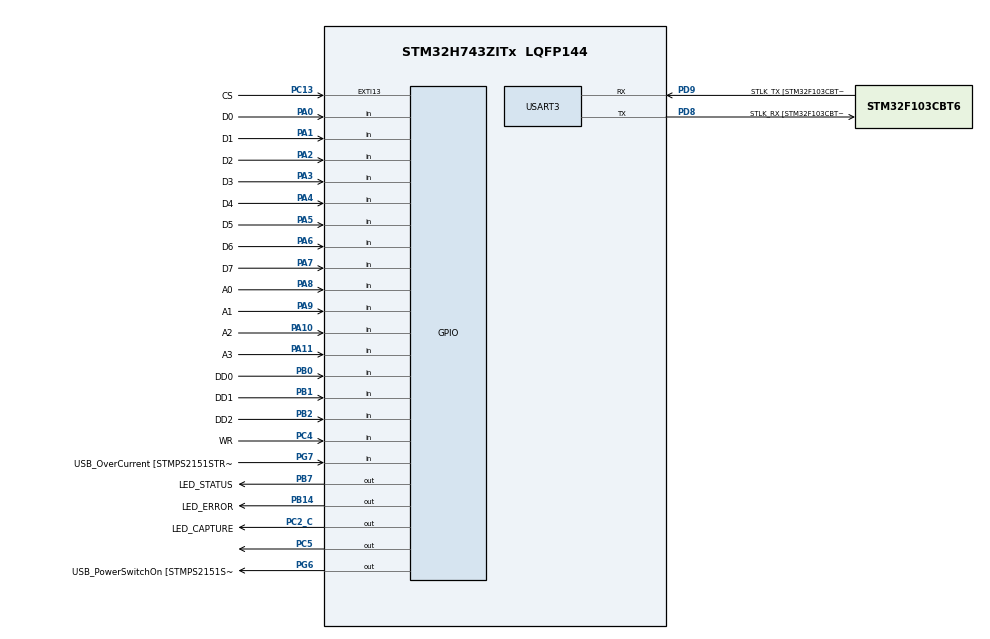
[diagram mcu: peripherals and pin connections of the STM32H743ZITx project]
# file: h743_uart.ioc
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Dma.Request0=USART3_TX
Dma.USART3_TX.0.Direction=DMA_MEMORY_TO_PERIPH
Dma.USART3_TX.0.EventEnable=DISABLE
Dma.USART3_TX.0.FIFOMode=DMA_FIFOMODE_DISABLE
Dma.USART3_TX.0.Instance=DMA1_Stream3
Dma.USART3_TX.0.MemDataAlignment=DMA_MDATAALIGN_BYTE
Dma.USART3_TX.0.MemInc=DMA_MINC_ENABLE
Dma.USART3_TX.0.Mode=DMA_NORMAL
Dma.USART3_TX.0.PeriphDataAlignment=DMA_PDATAALIGN_BYTE
Dma.USART3_TX.0.PeriphInc=DMA_PINC_DISABLE
Dma.USART3_TX.0.Polarity=HAL_DMAMUX_REQ_GEN_RISING
Dma.USART3_TX.0.Priority=DMA_PRIORITY_LOW
Dma.USART3_TX.0.RequestNumber=1
Dma.USART3_TX.0.SignalID=NONE
Dma.USART3_TX.0.SyncEnable=DISABLE
Dma.USART3_TX.0.SyncPolarity=HAL_DMAMUX_SYNC_NO_EVENT
Dma.USART3_TX.0.SyncRequestNumber=1
Dma.USART3_TX.0.SyncSignalID=NONE
Mcu.Family=STM32H7
Mcu.Name=STM32H743ZITx
Mcu.Package=LQFP144
NVIC.DMA1_Stream3_IRQn=true\:0\:0\:false\:false\:true\:false\:true
NVIC.EXTI15_10_IRQn=true\:0\:0\:false\:false\:true\:true\:true
NVIC.PriorityGroup=NVIC_PRIORITYGROUP_4
NVIC.USART3_IRQn=true\:0\:0\:false\:false\:true\:true\:true
PA0.GPIO_Label=D0
PA0.GPIO_PuPd=GPIO_NOPULL
PA0.Signal=GPIO_Input
PA1.GPIO_Label=D1
PA1.GPIO_PuPd=GPIO_NOPULL
PA1.Signal=GPIO_Input
PA10.GPIO_Label=A2
PA10.Signal=GPIO_Input
PA11.GPIO_Label=A3
PA11.Signal=GPIO_Input
PA12.GPIO_Label=USB_DP
PA12.Signal=USB_OTG_FS_DP
PA2.GPIO_Label=D2
PA2.GPIO_PuPd=GPIO_NOPULL
PA2.Signal=GPIO_Input
PA3.GPIO_Label=D3
PA3.Signal=GPIO_Input
PA4.GPIO_Label=D4
PA4.Signal=GPIO_Input
PA5.GPIO_Label=D5
PA5.Signal=GPIO_Input
PA6.GPIO_Label=D6
PA6.Signal=GPIO_Input
PA7.GPIO_Label=D7
PA7.Signal=GPIO_Input
PA8.GPIO_Label=A0
PA8.Signal=GPIO_Input
PA9.GPIO_Label=A1
PA9.Signal=GPIO_Input
PB0.GPIO_Label=DD0
PB0.GPIO_PuPd=GPIO_PULLUP
PB0.Signal=GPIO_Input
PB1.GPIO_Label=DD1
PB1.GPIO_PuPd=GPIO_PULLUP
PB1.Signal=GPIO_Input
PB13.GPIO_Label=RMII_TXD1
PB13.Signal=ETH_TXD1
PB14.GPIO_Label=LED_ERROR
PB14.GPIO_Speed=GPIO_SPEED_FREQ_VERY_HIGH
PB14.Signal=GPIO_Output
PB2.GPIO_Label=DD2
PB2.GPIO_PuPd=GPIO_PULLUP
PB2.Signal=GPIO_Input
PB7.GPIO_FM7=SYSCFG_PMCR_I2C_PB7_FMP
PB7.GPIO_Label=LED_STATUS
PB7.GPIO_Speed=GPIO_SPEED_FREQ_VERY_HIGH
PB7.Signal=GPIO_Output
PC1.GPIO_Label=RMII_MDC
PC1.Signal=ETH_MDC
PC13.GPIO_Label=CS
PC13.GPIO_ModeDefaultEXTI=GPIO_MODE_IT_FALLING
PC13.GPIO_PuPd=GPIO_PULLUP
PC13.Signal=GPXTI13
PC14-OSC32_IN\ (OSC32_IN).Mode=LSE-External-Oscillator
PC14-OSC32_IN\ (OSC32_IN).Signal=RCC_OSC32_IN
PC15-OSC32_OUT\ (OSC32_OUT).Mode=LSE-External-Oscillator
PC15-OSC32_OUT\ (OSC32_OUT).Signal=RCC_OSC32_OUT
PC2_C.GPIO_Label=LED_CAPTURE
PC2_C.GPIO_Speed=GPIO_SPEED_FREQ_VERY_HIGH
PC2_C.Signal=GPIO_Output
PC4.GPIO_Label=WR
PC4.GPIO_PuPd=GPIO_PULLUP
PC4.Signal=GPIO_Input
PC5.Signal=GPIO_Output
PD8.GPIO_Label=STLK_RX [STM32F103CBT6_PA3]
PD8.Mode=Asynchronous
PD8.Signal=USART3_TX
PD9.GPIO_Label=STLK_TX [STM32F103CBT6_PA2]
PD9.Mode=Asynchronous
PD9.Signal=USART3_RX
PG11.GPIO_Label=RMII_TX_EN
PG11.Signal=ETH_TX_EN
PG13.GPIO_Label=RMII_TXD0
PG13.Signal=ETH_TXD0
PG6.GPIO_Label=USB_PowerSwitchOn [STMPS2151STR_EN]
PG6.Signal=GPIO_Output
PG7.GPIO_Label=USB_OverCurrent [STMPS2151STR_FAULT]
PG7.Signal=GPIO_Input
PH0-OSC_IN\ (PH0).GPIO_Label=MCO
PH0-OSC_IN\ (PH0).Mode=HSE-External-Clock-Source
PH0-OSC_IN\ (PH0).Signal=RCC_OSC_IN
PH1-OSC_OUT\ (PH1).Signal=RCC_OSC_OUT
ProjectManager.HeapSize=0x200
ProjectManager.StackSize=0x1000
ProjectManager.TargetToolchain=STM32CubeIDE
RCC.48MHZClocksFreq_Value=24000000
RCC.ADCFreq_Value=16125000
RCC.AHBFreq_Value=216000000
RCC.APB1CLKDivider=RCC_HCLK_DIV4
RCC.APB1Freq_Value=120000000
RCC.APB1TimFreq_Value=108000000
RCC.APB2CLKDivider=RCC_HCLK_DIV2
RCC.APB2Freq_Value=120000000
RCC.APB2TimFreq_Value=216000000
RCC.APB3Freq_Value=120000000
RCC.APB4Freq_Value=120000000
RCC.CortexFreq_Value=480000000
RCC.D1PPRE=RCC_APB3_DIV2
RCC.D2PPRE1=RCC_APB1_DIV2
RCC.D2PPRE2=RCC_APB2_DIV2
RCC.D3PPRE=RCC_APB4_DIV2
RCC.DIVM1=1
RCC.DIVN1=120
RCC.DIVQ1=4
RCC.HCLKFreq_Value=240000000
RCC.HPRE=RCC_HCLK_DIV2
RCC.HSE_VALUE=8000000
RCC.HSI_VALUE=64000000
RCC.PLLFRACN=0
RCC.PLLM=25
RCC.PLLMUL=RCC_PLL_MUL9
RCC.PLLN=432
RCC.PLLQ=9
RCC.PLLSourceVirtual=RCC_PLLSOURCE_HSE
RCC.PRESCALERUSB=RCC_USBCLKSOURCE_PLL_DIV1_5
RCC.PWR_Regulator_Voltage_Scale=PWR_REGULATOR_VOLTAGE_SCALE0
RCC.SYSCLKFreq_VALUE=480000000
RCC.SYSCLKSource=RCC_SYSCLKSOURCE_PLLCLK
RCC.SYSCLKSourceVirtual=RCC_SYSCLKSOURCE_PLLCLK
RCC.USBFreq_Value=240000000
RCC.VCOOutputFreq_Value=432000000
USART3.VirtualMode-Asynchronous=VM_ASYNC
board=NUCLEO-H743ZI

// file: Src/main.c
/* USER CODE BEGIN Header */
/**
  ******************************************************************************
  * @file           : main.c
  * @brief          : Main program body
  ******************************************************************************
  * @attention
  *
  * <h2><center>&copy; Copyright (c) 2020 STMicroelectronics.
  * All rights reserved.</center></h2>
  *
  * This software component is licensed by ST under BSD 3-Clause license,
  * the "License"; You may not use this file except in compliance with the
  * License. You may obtain a copy of the License at:
  *                        opensource.org/licenses/BSD-3-Clause
  *
  ******************************************************************************
  */
/* USER CODE END Header */
#include "main.h"

/* USER CODE BEGIN Includes */
#include "ticker.h"
#include "frame.h"
#include "frame_com.h"
#include "evse_com_app.h"
#include "app_uart_fifo.h"
#include "serial3.h"
#include "io_input.h"
#include "input_service.h"
/* USER CODE END Includes */

UART_HandleTypeDef huart3;
DMA_HandleTypeDef hdma_usart3_tx;
DMA_HandleTypeDef hdma_usart3_rx;

/* USER CODE BEGIN PV */
static app_uart_fifo_ctx_t	uart_instance3;

static rfid_frame_handle_t	rfid_frame_handle;

static io_input_cxt_t            button_cxt     = IO_INPUT_DEFAULT;
static service_io_input_handle_t button_service = SERVICE_IO_INPUT_DEFAULT;
static ticker_function_handle_t  tick_button_sample;

static ticker_function_handle_t  tick_led_status;

static char const * button_serviceid[] = {
/* 0 */ "IO_INPUT_FALLING",
/* 1 */ "IO_INPUT_RISING",
/* 2 */ "BUTTON_SINGER_EVT",
/* 3 */ "BUTTON_DOUBLE_EVT",
/* 4 */ "BUTTON_HOLD_ON_EVT",
/* 5 */ "BUTTON_IDLE_EVT"
};

/* USER CODE END PV */

void SystemClock_Config(void);
static void MX_GPIO_Init(void);
static void MX_DMA_Init(void);
static void MX_USART3_UART_Init(void);

/* USER CODE BEGIN 0 */
/**
  * @brief  Tx Transfer completed callback
  * @param  huart: UART handle.
  * @note   This example shows a simple way to report end of DMA Tx transfer, and
  *         you can add your own implementation.
  * @retval None
  */
void HAL_UART_TxCpltCallback(UART_HandleTypeDef *huart)
{
	if (huart->Instance == USART3)
	{
		uart_instance3.irq_callback(&uart_instance3, APP_UART_IRQ_TX);
	}
}

void HAL_UART_RxCpltCallback(UART_HandleTypeDef *huart)
{
	if (huart->Instance == USART3)
	{
#if (defined APP_UART_FIFO_RX_DMA) && (APP_UART_FIFO_RX_DMA == 1)
		/* Get head position of rx_irq buffer
		 * __HAL_DMA_GET_COUNTER() is the macro return number of remaining data units in the current DMA Stream transfer */
		uart_instance3.rx_irq.head = uart_instance3.rx_irq.xfer_size - __HAL_DMA_GET_COUNTER(&hdma_usart3_rx);
		uart_instance3.irq_callback(&uart_instance3, APP_UART_IRQ_RX);
#else
		/* Get head position of rx_irq buffer
		* huart->RxXferCount shall return number of remaining data units in the current rx_irq buffer */
		uart_instance3.rx_irq.head = uart_instance3.rx_irq.xfer_size - huart->RxXferCount;
		uart_instance3.irq_callback(&uart_instance3, APP_UART_IRQ_RX);
#endif
	}
}

void HAL_UART_RxHalfCpltCallback(UART_HandleTypeDef *huart)
{
	if (huart->Instance == USART3)
	{
#if (defined APP_UART_FIFO_RX_DMA) && (APP_UART_FIFO_RX_DMA == 1)
		/* Get head position of rx_irq buffer
		 * __HAL_DMA_GET_COUNTER() is the macro return number of remaining data units in the current DMA Stream transfer */
		uart_instance3.rx_irq.head = uart_instance3.rx_irq.xfer_size - __HAL_DMA_GET_COUNTER(&hdma_usart3_rx);
		/* Using case APP_UART_IRQ_IDLE instead APP_UART_IRQ_RX because this isn't irq complete yet */
		uart_instance3.irq_callback(&uart_instance3, APP_UART_IRQ_IDLE);
#else
		/* Get head position of rx_irq buffer
		* huart->RxXferCount shall return number of remaining data units in the current rx_irq buffer */
		uart_instance3.rx_irq.head = uart_instance3.rx_irq.xfer_size - huart->RxXferCount;
		/* Using case APP_UART_IRQ_IDLE instead APP_UART_IRQ_RX because this isn't irq complete yet */
		uart_instance3.irq_callback(&uart_instance3, APP_UART_IRQ_IDLE);
#endif
	}
}

void USART_IDLE_line_IRQHandler(UART_HandleTypeDef *huart)
{
	if (huart->Instance == USART3)
	{
		if (__HAL_UART_GET_FLAG(huart, UART_FLAG_IDLE))
		{
			/* Clear IDLE line flag */
			__HAL_UART_CLEAR_FLAG(huart, UART_CLEAR_IDLEF);

#if (defined APP_UART_FIFO_RX_DMA) && (APP_UART_FIFO_RX_DMA == 1)
			/* Get head position of rx_irq buffer
			 * __HAL_DMA_GET_COUNTER() is the macro return number of remaining data units in the current DMA Stream transfer */
			uart_instance3.rx_irq.head = uart_instance3.rx_irq.xfer_size - __HAL_DMA_GET_COUNTER(&hdma_usart3_rx);
			/* Using case APP_UART_IRQ_IDLE instead APP_UART_IRQ_RX because this isn't irq complete yet */
			uart_instance3.irq_callback(&uart_instance3, APP_UART_IRQ_IDLE);
#else
			/* Get head position of rx_irq buffer
			* huart->RxXferCount shall return number of remaining data units in the current rx_irq buffer */
			uart_instance3.rx_irq.head = uart_instance3.rx_irq.xfer_size - huart->RxXferCount;
			/* Using case APP_UART_IRQ_IDLE instead APP_UART_IRQ_RX because this isn't irq complete yet */
			uart_instance3.irq_callback(&uart_instance3, APP_UART_IRQ_IDLE);
#endif
		}
	}
}

/* Event callback app_uart_fifo */
static void uart_instance3_event_handle(struct app_uart_fifo_ctx *p_app_cxt, app_uart_evt_t *p_event)
{
	if (p_app_cxt == &uart_instance3)
	{
		switch (p_event->evt_type)
		{
		case EVT_APP_UART_TX_READY:
			break;

		case EVT_APP_UART_RX_READY:
			break;

		case EVT_APP_UART_TX_EMPTY:
			break;

		case EVT_APP_UART_RX_EMPTY:
			break;

		case EVT_APP_UART_TX_OVER:
			break;

		case EVT_APP_UART_RX_OVER:
			break;

		case EVT_APP_UART_DATA_READY:
			break;

		case EVT_APP_UART_DATA_SENDING:
			break;

		case EVT_APP_UART_TX_FIFO_ERROR:
			break;

		case EVT_APP_UART_RX_FIFO_ERROR:
			break;

		case EVT_APP_UART_COMMUNICATION_ERROR:
			break;

		default:
			break;
		}
	}
}

/* callback uart transmit start
 * Using DMA Tx
 * */
static void uart_instance3_transmit_start_cb(uint8_t *p_data, uint32_t lenght)
{
	HAL_UART_Transmit_DMA(&huart3, p_data, lenght);
}

/* callback uart receive start
 * Using Interrupt rx
 * */
static void uart_instance3_receive_start_cb(uint8_t *p_data, uint32_t lenght)
{
#if (defined APP_UART_FIFO_RX_DMA) && (APP_UART_FIFO_RX_DMA == 1)
	HAL_UART_Receive_DMA(&huart3, p_data, lenght);
#else
	HAL_UART_Receive_IT(&huart3, p_data, lenght);
#endif
}

/* Brief: the function shall called when Mifare card detected
 * UID of mifare card command callback
 * UID: 0xD2 0xEF 0x46 0xD2
 * Test case:
 * Hex string 0x7E 0x12 0x01 0xD2 0xEF 0x46 0xD2 0x00 0x00 0x00 0x00 0x00 0x00 0x00 0x00 0x00 0x00 0x00 0xA9 0x13 0x7F
 * Hercules terminal test string: $7E$12$01$D2$EF$46$D2$00$00$00$00$00$00$00$00$00$00$00$A9$13$7F
 * */
static void rfid_uid_callback(uint8_t* uid, uint8_t length)
{
	_PRINTF("\r\n====================");
	_PRINTF("\r\nUID Mifare Card: ");
	for(uint8_t i = 0; i < length; ++i)
	{
		_PRINTF("%02X ",uid[i]);
	}
	_PRINTF("\r\n====================");
	_PRINTF("\r\n");
}

void led_status_blink_cb(uint32_t remain)
{
  HAL_GPIO_TogglePin(GPIOB, LED_STATUS_Pin);
}

/*  */
void button_sample_rate_cb(uint32_t remain)
{
  uint8_t ip_status;
  (void)remain;

  ip_status = HAL_GPIO_ReadPin(USER_BUTTON_GPIO_Port, USER_BUTTON_Pin);
  io_input_process(&button_cxt, ip_status);
}

void button_service_cb(service_io_input_handle_t *service, uint8_t evt)
{
  _PRINTF("\r\nButton service: %s", button_serviceid[evt]);
  _PRINTF("\r\n");
  if (service == &button_service)
  {
    switch (evt)
    {
    case IO_INPUT_FALLING:
      break;

    case IO_INPUT_RISING:
      break;

    case BUTTON_SINGER_EVT:
      break;

    case BUTTON_DOUBLE_EVT:
      break;

    case BUTTON_HOLD_ON_EVT:
      break;

    case BUTTON_IDLE_EVT:
      break;

    default:
      break;
    }
  }
}
/* USER CODE END 0 */

int main(void)
{

  /* MCU Configuration--------------------------------------------------------*/

  /* Reset of all peripherals, Initializes the Flash interface and the Systick. */
  HAL_Init();

  /* Configure the system clock */
  SystemClock_Config();

  /* Initialize all configured peripherals */
  MX_GPIO_Init();
  MX_DMA_Init();
  MX_USART3_UART_Init();
  /* USER CODE BEGIN 2 */

  /* Init object app_uart_fifo */
  uart_instance3.fp_transmit = uart_instance3_transmit_start_cb;
  uart_instance3.fp_receive = uart_instance3_receive_start_cb;
  uart_instance3.fp_event = uart_instance3_event_handle;
  uart_instance3_Init(&uart_instance3);

  /* Register serial interface with rfid */
  rfid_frame_handle.input_cb = getchar_instance3;    /* serial3 input callback */
  rfid_frame_handle.output_cb = putchar_instance3;   /* serial3 output callback */
  rfid_frame_handle.uid_cb = rfid_uid_callback;
  evse_handle_init(&rfid_frame_handle);

  /* USER CODE END 2 */

  /* Infinite loop */
  /* USER CODE BEGIN WHILE */

  button_service.evt_cb = button_service_cb;
  button_service.edge_release = IO_FALLING;
  button_service.level_active = IO_HIGH;
  io_input_init(&button_cxt, 5, 5); /* 5 is high and low sample rate count*/
  service_io_input_init(&button_cxt, &button_service);
  /* Init tick sample rate 10ms */
  ticker_function_init(&tick_button_sample, button_sample_rate_cb, 10, TICKER_FOREVER);

  /* Init tick led status blink */
  ticker_function_init(&tick_led_status, led_status_blink_cb, 300, TICKER_FOREVER);

  UART_INSTANCE3_PRINTF("\r\nSerial frame communication V1.0.1\n\r");
  while (1)
  {
	/* EVSE handle process */
	evse_handle_loop();

	/* timer ticker process handler */
	ticker_loop();

    /* USER CODE END WHILE */

  }
}

void SystemClock_Config(void)
{
  RCC_OscInitTypeDef RCC_OscInitStruct = {0};
  RCC_ClkInitTypeDef RCC_ClkInitStruct = {0};
  RCC_PeriphCLKInitTypeDef PeriphClkInitStruct = {0};

  /** Supply configuration update enable
  */
  HAL_PWREx_ConfigSupply(PWR_LDO_SUPPLY);
  /** Configure the main internal regulator output voltage
  */
  __HAL_PWR_VOLTAGESCALING_CONFIG(PWR_REGULATOR_VOLTAGE_SCALE0);

  while(!__HAL_PWR_GET_FLAG(PWR_FLAG_VOSRDY)) {}
  /** Initializes the RCC Oscillators according to the specified parameters
  * in the RCC_OscInitTypeDef structure.
  */
  RCC_OscInitStruct.OscillatorType = RCC_OSCILLATORTYPE_HSE;
  RCC_OscInitStruct.HSEState = RCC_HSE_BYPASS;
  RCC_OscInitStruct.PLL.PLLState = RCC_PLL_ON;
  RCC_OscInitStruct.PLL.PLLSource = RCC_PLLSOURCE_HSE;
  RCC_OscInitStruct.PLL.PLLM = 1;
  RCC_OscInitStruct.PLL.PLLN = 120;
  RCC_OscInitStruct.PLL.PLLP = 2;
  RCC_OscInitStruct.PLL.PLLQ = 4;
  RCC_OscInitStruct.PLL.PLLR = 2;
  RCC_OscInitStruct.PLL.PLLRGE = RCC_PLL1VCIRANGE_3;
  RCC_OscInitStruct.PLL.PLLVCOSEL = RCC_PLL1VCOWIDE;
  RCC_OscInitStruct.PLL.PLLFRACN = 0;
  if (HAL_RCC_OscConfig(&RCC_OscInitStruct) != HAL_OK)
  {
    Error_Handler();
  }
  /** Initializes the CPU, AHB and APB buses clocks
  */
  RCC_ClkInitStruct.ClockType = RCC_CLOCKTYPE_HCLK|RCC_CLOCKTYPE_SYSCLK
                              |RCC_CLOCKTYPE_PCLK1|RCC_CLOCKTYPE_PCLK2
                              |RCC_CLOCKTYPE_D3PCLK1|RCC_CLOCKTYPE_D1PCLK1;
  RCC_ClkInitStruct.SYSCLKSource = RCC_SYSCLKSOURCE_PLLCLK;
  RCC_ClkInitStruct.SYSCLKDivider = RCC_SYSCLK_DIV1;
  RCC_ClkInitStruct.AHBCLKDivider = RCC_HCLK_DIV2;
  RCC_ClkInitStruct.APB3CLKDivider = RCC_APB3_DIV2;
  RCC_ClkInitStruct.APB1CLKDivider = RCC_APB1_DIV2;
  RCC_ClkInitStruct.APB2CLKDivider = RCC_APB2_DIV2;
  RCC_ClkInitStruct.APB4CLKDivider = RCC_APB4_DIV2;

  if (HAL_RCC_ClockConfig(&RCC_ClkInitStruct, FLASH_LATENCY_4) != HAL_OK)
  {
    Error_Handler();
  }
  PeriphClkInitStruct.PeriphClockSelection = RCC_PERIPHCLK_USART3;
  PeriphClkInitStruct.Usart234578ClockSelection = RCC_USART234578CLKSOURCE_D2PCLK1;
  if (HAL_RCCEx_PeriphCLKConfig(&PeriphClkInitStruct) != HAL_OK)
  {
    Error_Handler();
  }
}

static void MX_USART3_UART_Init(void)
{

  huart3.Instance = USART3;
  huart3.Init.BaudRate = 115200;
  huart3.Init.WordLength = UART_WORDLENGTH_8B;
  huart3.Init.StopBits = UART_STOPBITS_1;
  huart3.Init.Parity = UART_PARITY_NONE;
  huart3.Init.Mode = UART_MODE_TX_RX;
  huart3.Init.HwFlowCtl = UART_HWCONTROL_NONE;
  huart3.Init.OverSampling = UART_OVERSAMPLING_16;
  huart3.Init.OneBitSampling = UART_ONE_BIT_SAMPLE_DISABLE;
  huart3.Init.ClockPrescaler = UART_PRESCALER_DIV1;
  huart3.AdvancedInit.AdvFeatureInit = UART_ADVFEATURE_NO_INIT;
  if (HAL_UART_Init(&huart3) != HAL_OK)
  {
    Error_Handler();
  }
  if (HAL_UARTEx_SetTxFifoThreshold(&huart3, UART_TXFIFO_THRESHOLD_1_8) != HAL_OK)
  {
    Error_Handler();
  }
  if (HAL_UARTEx_SetRxFifoThreshold(&huart3, UART_RXFIFO_THRESHOLD_1_8) != HAL_OK)
  {
    Error_Handler();
  }
  if (HAL_UARTEx_DisableFifoMode(&huart3) != HAL_OK)
  {
    Error_Handler();
  }
  /* USER CODE BEGIN USART3_Init 2 */
  __HAL_UART_ENABLE_IT(&huart3, UART_IT_IDLE);
  /* USER CODE END USART3_Init 2 */

}

static void MX_DMA_Init(void)
{

  /* DMA controller clock enable */
  __HAL_RCC_DMA1_CLK_ENABLE();

  /* DMA interrupt init */
  /* DMA1_Stream0_IRQn interrupt configuration */
  HAL_NVIC_SetPriority(DMA1_Stream0_IRQn, 0, 0);
  HAL_NVIC_EnableIRQ(DMA1_Stream0_IRQn);
  /* DMA1_Stream3_IRQn interrupt configuration */
  HAL_NVIC_SetPriority(DMA1_Stream3_IRQn, 0, 0);
  HAL_NVIC_EnableIRQ(DMA1_Stream3_IRQn);

}

static void MX_GPIO_Init(void)
{
  GPIO_InitTypeDef GPIO_InitStruct = {0};

  /* GPIO Ports Clock Enable */
  __HAL_RCC_GPIOC_CLK_ENABLE();
  __HAL_RCC_GPIOH_CLK_ENABLE();
  __HAL_RCC_GPIOA_CLK_ENABLE();
  __HAL_RCC_GPIOB_CLK_ENABLE();
  __HAL_RCC_GPIOD_CLK_ENABLE();
  __HAL_RCC_GPIOG_CLK_ENABLE();

  /*Configure GPIO pin Output Level */
  HAL_GPIO_WritePin(GPIOC, LED_CAPTURE_Pin|GPIO_PIN_5, GPIO_PIN_RESET);

  /*Configure GPIO pin Output Level */
  HAL_GPIO_WritePin(GPIOB, LED_ERROR_Pin|LED_STATUS_Pin, GPIO_PIN_RESET);

  /*Configure GPIO pin Output Level */
  HAL_GPIO_WritePin(USB_PowerSwitchOn_GPIO_Port, USB_PowerSwitchOn_Pin, GPIO_PIN_RESET);

  /*Configure GPIO pin : USER_BUTTON_Pin */
  GPIO_InitStruct.Pin = USER_BUTTON_Pin;
  GPIO_InitStruct.Mode = GPIO_MODE_INPUT;
  GPIO_InitStruct.Pull = GPIO_NOPULL;
  HAL_GPIO_Init(USER_BUTTON_GPIO_Port, &GPIO_InitStruct);

  /*Configure GPIO pin : RMII_MDC_Pin */
  GPIO_InitStruct.Pin = RMII_MDC_Pin;
  GPIO_InitStruct.Mode = GPIO_MODE_AF_PP;
  GPIO_InitStruct.Pull = GPIO_NOPULL;
  GPIO_InitStruct.Speed = GPIO_SPEED_FREQ_LOW;
  GPIO_InitStruct.Alternate = GPIO_AF11_ETH;
  HAL_GPIO_Init(RMII_MDC_GPIO_Port, &GPIO_InitStruct);

  /*Configure GPIO pin : LED_CAPTURE_Pin */
  GPIO_InitStruct.Pin = LED_CAPTURE_Pin;
  GPIO_InitStruct.Mode = GPIO_MODE_OUTPUT_PP;
  GPIO_InitStruct.Pull = GPIO_NOPULL;
  GPIO_InitStruct.Speed = GPIO_SPEED_FREQ_VERY_HIGH;
  HAL_GPIO_Init(LED_CAPTURE_GPIO_Port, &GPIO_InitStruct);

  /*Configure GPIO pins : D0_Pin D1_Pin D2_Pin D3_Pin
                           D4_Pin D5_Pin D6_Pin D7_Pin
                           A0_Pin A1_Pin A2_Pin A3_Pin */
  GPIO_InitStruct.Pin = D0_Pin|D1_Pin|D2_Pin|D3_Pin
                          |D4_Pin|D5_Pin|D6_Pin|D7_Pin
                          |A0_Pin|A1_Pin|A2_Pin|A3_Pin;
  GPIO_InitStruct.Mode = GPIO_MODE_INPUT;
  GPIO_InitStruct.Pull = GPIO_NOPULL;
  HAL_GPIO_Init(GPIOA, &GPIO_InitStruct);

  /*Configure GPIO pin : WR_Pin */
  GPIO_InitStruct.Pin = WR_Pin;
  GPIO_InitStruct.Mode = GPIO_MODE_INPUT;
  GPIO_InitStruct.Pull = GPIO_PULLUP;
  HAL_GPIO_Init(WR_GPIO_Port, &GPIO_InitStruct);

  /*Configure GPIO pin : PC5 */
  GPIO_InitStruct.Pin = GPIO_PIN_5;
  GPIO_InitStruct.Mode = GPIO_MODE_OUTPUT_PP;
  GPIO_InitStruct.Pull = GPIO_NOPULL;
  GPIO_InitStruct.Speed = GPIO_SPEED_FREQ_LOW;
  HAL_GPIO_Init(GPIOC, &GPIO_InitStruct);

  /*Configure GPIO pins : DD0_Pin DD1_Pin DD2_Pin */
  GPIO_InitStruct.Pin = DD0_Pin|DD1_Pin|DD2_Pin;
  GPIO_InitStruct.Mode = GPIO_MODE_INPUT;
  GPIO_InitStruct.Pull = GPIO_PULLUP;
  HAL_GPIO_Init(GPIOB, &GPIO_InitStruct);

  /*Configure GPIO pin : RMII_TXD1_Pin */
  GPIO_InitStruct.Pin = RMII_TXD1_Pin;
  GPIO_InitStruct.Mode = GPIO_MODE_AF_PP;
  GPIO_InitStruct.Pull = GPIO_NOPULL;
  GPIO_InitStruct.Speed = GPIO_SPEED_FREQ_LOW;
  GPIO_InitStruct.Alternate = GPIO_AF11_ETH;
  HAL_GPIO_Init(RMII_TXD1_GPIO_Port, &GPIO_InitStruct);

  /*Configure GPIO pins : LED_ERROR_Pin LED_STATUS_Pin */
  GPIO_InitStruct.Pin = LED_ERROR_Pin|LED_STATUS_Pin;
  GPIO_InitStruct.Mode = GPIO_MODE_OUTPUT_PP;
  GPIO_InitStruct.Pull = GPIO_NOPULL;
  GPIO_InitStruct.Speed = GPIO_SPEED_FREQ_VERY_HIGH;
  HAL_GPIO_Init(GPIOB, &GPIO_InitStruct);

  /*Configure GPIO pin : USB_PowerSwitchOn_Pin */
  GPIO_InitStruct.Pin = USB_PowerSwitchOn_Pin;
  GPIO_InitStruct.Mode = GPIO_MODE_OUTPUT_PP;
  GPIO_InitStruct.Pull = GPIO_NOPULL;
  GPIO_InitStruct.Speed = GPIO_SPEED_FREQ_LOW;
  HAL_GPIO_Init(USB_PowerSwitchOn_GPIO_Port, &GPIO_InitStruct);

  /*Configure GPIO pin : USB_OverCurrent_Pin */
  GPIO_InitStruct.Pin = USB_OverCurrent_Pin;
  GPIO_InitStruct.Mode = GPIO_MODE_INPUT;
  GPIO_InitStruct.Pull = GPIO_NOPULL;
  HAL_GPIO_Init(USB_OverCurrent_GPIO_Port, &GPIO_InitStruct);

  /*Configure GPIO pin : USB_DP_Pin */
  GPIO_InitStruct.Pin = USB_DP_Pin;
  GPIO_InitStruct.Mode = GPIO_MODE_AF_PP;
  GPIO_InitStruct.Pull = GPIO_NOPULL;
  GPIO_InitStruct.Speed = GPIO_SPEED_FREQ_LOW;
  GPIO_InitStruct.Alternate = GPIO_AF10_OTG1_FS;
  HAL_GPIO_Init(USB_DP_GPIO_Port, &GPIO_InitStruct);

  /*Configure GPIO pins : RMII_TX_EN_Pin RMII_TXD0_Pin */
  GPIO_InitStruct.Pin = RMII_TX_EN_Pin|RMII_TXD0_Pin;
  GPIO_InitStruct.Mode = GPIO_MODE_AF_PP;
  GPIO_InitStruct.Pull = GPIO_NOPULL;
  GPIO_InitStruct.Speed = GPIO_SPEED_FREQ_LOW;
  GPIO_InitStruct.Alternate = GPIO_AF11_ETH;
  HAL_GPIO_Init(GPIOG, &GPIO_InitStruct);

  /**/
  HAL_I2CEx_EnableFastModePlus(SYSCFG_PMCR_I2C_PB7_FMP);

}

void Error_Handler(void)
{
}

/************************ (C) COPYRIGHT STMicroelectronics *****END OF FILE****/
